# AUX_EVCTL register map
Vendor: Texas Instruments
Peripheral module from a debugger description file (folder CC26x1x3).
Registers are 32-bit, access per field, reset 0x0 unless marked. A register's access mark holds for its fields unless they carry their own. Offsets are as the file gives them; lines under a group give offsets from that group; [hi:lo] are bit positions; {n}, {i} and the like mark numbered series; 'fields as' and 'values as' point back to an identical list; <NAME> marks a mode.

## AUX_EVCTL — AUX Event Controller (AUX_EVCTL) assembles events originating from: - AUX submodules, including ADC and comparators. - AUXIO. - EVENT. - AON_PMCTL. - AON_RTC. into two 64-bit event buses. One is synchronized to the AUX clock and one is left unsynchronized. The subscribers to the synchronous event bus are AUX_TIMER01 and AUX_EVCTL. The subscribers to the asynchronous event bus are AUX_ANAIF, AUX_TDC and AUX_SYSIF. AUX_EVCTL uses the synchronous event bus to generate events to AON_EVENT and EVENT.
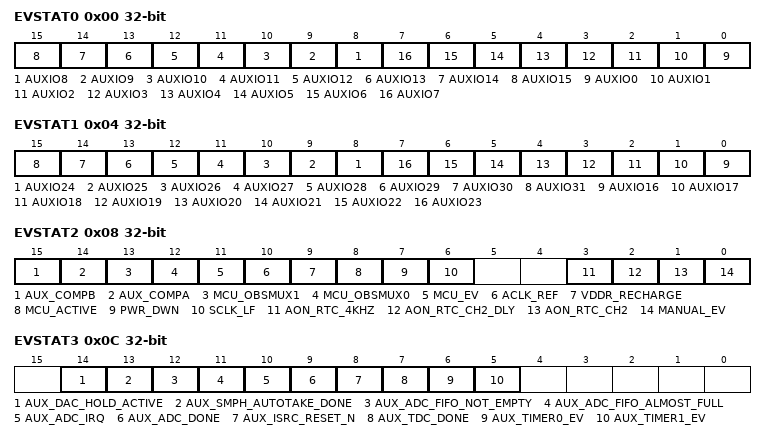
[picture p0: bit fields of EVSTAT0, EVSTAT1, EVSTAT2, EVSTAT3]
0x00 EVSTAT0 ro — Event Status 0 Register holds events 0 thru 15 of the 64-bit event bus that is synchronous to AUX clock. All events read through this register are synchronized at SCE clock rate, unless otherwise noted. The following subscribers use the asynchronous version of events in this register. - AUX_ANAIF. - AUX_TDC. - AUX_SYSIF. - AUX_AIODIOn. - EVOBSCFG.
  [n] AUXIO{n} (n=8..15) — AUXIO{n} pin level, read value corresponds to AUX_AIODIO1:GPIODIN bit {n-8}.
  [n] AUXIO{n} (n=0..7) — AUXIO{n} pin level, read value corresponds to AUX_AIODIO0:GPIODIN bit {n}.
0x04 EVSTAT1 ro — Event Status 1 Register holds events 16 thru 31 of the 64-bit event bus that is synchronous to AUX clock. All events read through this register are synchronized at SCE clock rate, unless otherwise noted. The following subscribers use the asynchronous version of events in this register. - AUX_ANAIF. - AUX_TDC. - AUX_SYSIF. - AUX_AIODIOn. - EVOBSCFG.
  [n-16] AUXIO{n} (n=24..31) — AUXIO{n} pin level, read value corresponds to AUX_AIODIO3:GPIODIN bit {n-24}.
  [n-16] AUXIO{n} (n=16..23) — AUXIO{n} pin level, read value corresponds to AUX_AIODIO2:GPIODIN bit {n-16}.
0x08 EVSTAT2 ro — Event Status 2 Register holds events 32 thru 47 of the 64-bit event bus that is synchronous to AUX clock. All events read through this register are synchronized at SCE clock rate, unless otherwise noted. The following subscribers use the asynchronous version of events in this register. - AUX_ANAIF. - AUX_TDC. - AUX_SYSIF. - AUX_AIODIOn. - EVOBSCFG.
  [15] AUX_COMPB — Comparator B output. Configuration of AUX_SYSIF:EVSYNCRATE.AUX_COMPB_SYNC_RATE sets the synchronization rate for this event.
  [14] AUX_COMPA — Comparator A output. Configuration of AUX_SYSIF:EVSYNCRATE.AUX_COMPA_SYNC_RATE sets the synchronization rate for this event.
  [13] MCU_OBSMUX1 — Observation input 1 from IOC. This event is configured by IOC:OBSAUXOUTPUT.SEL1.
  [12] MCU_OBSMUX0 — Observation input 0 from IOC. This event is configured by IOC:OBSAUXOUTPUT.SEL0 and can be overridden by IOC:OBSAUXOUTPUT.SEL_MISC.
  [11] MCU_EV — Event from EVENT configured by EVENT:AUXSEL0.
  [10] ACLK_REF — TDC reference clock. It is configured by DDI_0_OSC:CTL0.ACLK_REF_SRC_SEL and enabled by AUX_SYSIF:TDCREFCLKCTL.REQ.
  [9] VDDR_RECHARGE — Event is high during VDDR recharge.
  [8] MCU_ACTIVE — Event is high while system(MCU, AUX, or JTAG domains) is active or transitions to active (GLDO or DCDC power supply state). Event is not high during VDDR recharge.
  [7] PWR_DWN — Event is high while system(MCU, AUX, or JTAG domains) is in powerdown (uLDO power supply).
  [6] SCLK_LF — SCLK_LF clock
  [3] AON_RTC_4KHZ — AON_RTC:SUBSEC.VALUE bit 19. AON_RTC:CTL.RTC_4KHZ_EN enables this event.
  [2] AON_RTC_CH2_DLY — AON_RTC:EVFLAGS.CH2 delayed by AON_RTC:CTL.EV_DELAY configuration.
  [1] AON_RTC_CH2 — AON_RTC:EVFLAGS.CH2.
  [0] MANUAL_EV — Programmable event. See MANUAL for description.
0x0C EVSTAT3 ro — Event Status 3 Register holds events 48 thru 63 of the 64-bit event bus that is synchronous to AUX clock. All events read through this register are synchronized at SCE clock rate, unless otherwise noted. The following subscribers use the asynchronous version of events in this register. - AUX_ANAIF. - AUX_TDC . - AUX_SYSIF. - AUX_AIODIOn. - EVOBSCFG.
  [14] AUX_DAC_HOLD_ACTIVE — AUX_ANAIF:DACSTAT.HOLD_ACTIVE
  [13] AUX_SMPH_AUTOTAKE_DONE — See AUX_SMPH:AUTOTAKE.SMPH_ID for description.
  [12] AUX_ADC_FIFO_NOT_EMPTY — AUX_ANAIF:ADCFIFOSTAT.EMPTY negated
  [11] AUX_ADC_FIFO_ALMOST_FULL — AUX_ANAIF:ADCFIFOSTAT.ALMOST_FULL
  [10] AUX_ADC_IRQ — The logical function for this event is configurable. When DMACTL.EN = 1 : Event = UDMA0 Channel 7 done event OR AUX_ANAIF:ADCFIFOSTAT.OVERFLOW OR AUX_ANAIF:ADCFIFOSTAT.UNDERFLOW When DMACTL.EN = 0 : Event = (NOT AUX_ANAIF:ADCFIFOSTAT.EMPTY) OR AUX_ANAIF:ADCFIFOSTAT.OVERFLOW OR AUX_ANAIF:ADCFIFOSTAT.UNDERFLOW Bit 7 in UDMA0:DONEMASK must be 0.
  [9] AUX_ADC_DONE — AUX_ANAIF ADC conversion done event. Event is synchronized at AUX bus rate.
  [8] AUX_ISRC_RESET_N — AUX_ANAIF:ISRCCTL.RESET_N
  [7] AUX_TDC_DONE — AUX_TDC:STAT.DONE
  [6] AUX_TIMER0_EV — AUX_TIMER0_EV event, see AUX_TIMER01:T0TARGET for description.
  [5] AUX_TIMER1_EV — AUX_TIMER1_EV event, see AUX_TIMER01:T1TARGET for description.
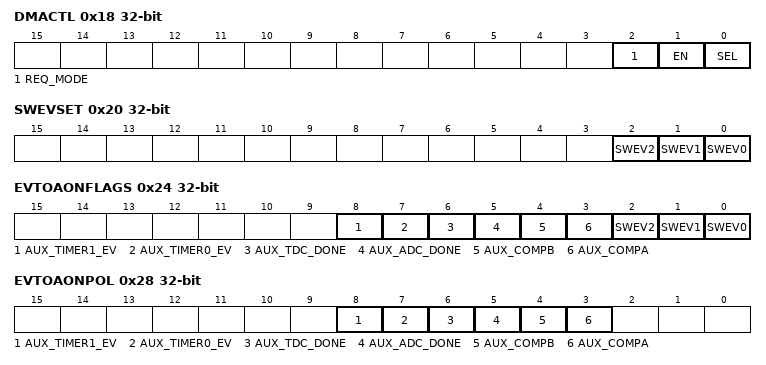
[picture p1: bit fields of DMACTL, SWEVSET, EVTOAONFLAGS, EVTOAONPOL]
0x18 DMACTL — Direct Memory Access Control
  [2] REQ_MODE rw — UDMA0 Request mode
    1=SINGLE (Single requests are generated on UDMA0 channel 7 when the condition configured in SEL is met.); 0=BURST (Burst requests are generated on UDMA0 channel 7 when the condition configured in SEL is met.)
  [1] EN rw — uDMA ADC interface enable. 0: Disable UDMA0 interface to ADC. 1: Enable UDMA0 interface to ADC.
  [0] SEL rw — Select FIFO watermark level required to trigger a UDMA0 transfer of ADC FIFO data.
    1=AUX_ADC_FIFO_ALMOST_FULL (UDMA0 trigger event will be generated when the ADC FIFO is almost full (3/4 full).); 0=AUX_ADC_FIFO_NOT_EMPTY (UDMA0 trigger event will be generated when there are samples in the ADC FIFO.)
0x20 SWEVSET — Software Event Set Set software event flags from AUX domain to AON and MCU domains. CPUs in MCU domain can read the event flags from EVTOAONFLAGS and clear them in EVTOAONFLAGSCLR. Use of these event flags is software-defined.
  [2] SWEV2 wo — Software event flag 2. 0: No effect. 1: Set software event flag 2.
  [1] SWEV1 wo — Software event flag 1. 0: No effect. 1: Set software event flag 1.
  [0] SWEV0 wo — Software event flag 0. 0: No effect. 1: Set software event flag 0.
0x24 EVTOAONFLAGS — Events To AON Flags This register contains a collection of event flags routed to AON_EVENT. To clear an event flag, write to EVTOAONFLAGSCLR or write 0 to event flag in this register.
  [8] AUX_TIMER1_EV rw — This event flag is set when level selected by EVTOAONPOL.AUX_TIMER1_EV occurs on EVSTAT3.AUX_TIMER1_EV.
  [7] AUX_TIMER0_EV rw — This event flag is set when level selected by EVTOAONPOL.AUX_TIMER0_EV occurs on EVSTAT3.AUX_TIMER0_EV.
  [6] AUX_TDC_DONE rw — This event flag is set when level selected by EVTOAONPOL.AUX_TDC_DONE occurs on EVSTAT3.AUX_TDC_DONE.
  [5] AUX_ADC_DONE rw — This event flag is set when level selected by EVTOAONPOL.AUX_ADC_DONE occurs on EVSTAT3.AUX_ADC_DONE.
  [4] AUX_COMPB rw — This event flag is set when edge selected by EVTOAONPOL.AUX_COMPB occurs on EVSTAT2.AUX_COMPB.
  [3] AUX_COMPA rw — This event flag is set when edge selected by EVTOAONPOL.AUX_COMPA occurs on EVSTAT2.AUX_COMPA.
  [2] SWEV2 rw — This event flag is set when software writes a 1 to SWEVSET.SWEV2.
  [1] SWEV1 rw — This event flag is set when software writes a 1 to SWEVSET.SWEV1.
  [0] SWEV0 rw — This event flag is set when software writes a 1 to SWEVSET.SWEV0.
0x28 EVTOAONPOL — Events To AON Polarity Event source polarity configuration for EVTOAONFLAGS.
  [8] AUX_TIMER1_EV rw — Select the level of EVSTAT3.AUX_TIMER1_EV that sets EVTOAONFLAGS.AUX_TIMER1_EV.
    1=LOW (Low level); 0=HIGH (High level)
  [7] AUX_TIMER0_EV rw — Select the level of EVSTAT3.AUX_TIMER0_EV that sets EVTOAONFLAGS.AUX_TIMER0_EV.
    1=LOW (Low level); 0=HIGH (High level)
  [6] AUX_TDC_DONE rw — Select level of EVSTAT3.AUX_TDC_DONE that sets EVTOAONFLAGS.AUX_TDC_DONE.
    1=LOW (Low level); 0=HIGH (High level)
  [5] AUX_ADC_DONE rw — Select the level of EVSTAT3.AUX_ADC_DONE that sets EVTOAONFLAGS.AUX_ADC_DONE.
    1=LOW (Low level); 0=HIGH (High level)
  [4] AUX_COMPB rw — Select the edge of EVSTAT2.AUX_COMPB that sets EVTOAONFLAGS.AUX_COMPB.
    1=FALL (Falling edge); 0=RISE (Rising edge)
  [3] AUX_COMPA rw — Select the edge of EVSTAT2.AUX_COMPA that sets EVTOAONFLAGS.AUX_COMPA.
    1=FALL (Falling edge); 0=RISE (Rising edge)
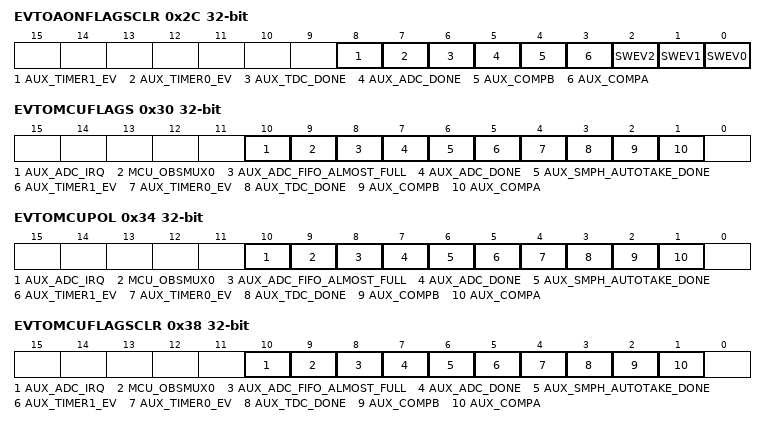
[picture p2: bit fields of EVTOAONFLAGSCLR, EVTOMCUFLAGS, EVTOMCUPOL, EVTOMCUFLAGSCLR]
0x2C EVTOAONFLAGSCLR — Events To AON Clear Clear event flags in EVTOAONFLAGS. In order to clear a level sensitive event flag, the event must be deasserted.
  [8] AUX_TIMER1_EV wo — Write 1 to clear EVTOAONFLAGS.AUX_TIMER1_EV. Read value is 0.
  [7] AUX_TIMER0_EV wo — Write 1 to clear EVTOAONFLAGS.AUX_TIMER0_EV. Read value is 0.
  [6] AUX_TDC_DONE wo — Write 1 to clear EVTOAONFLAGS.AUX_TDC_DONE. Read value is 0.
  [5] AUX_ADC_DONE wo — Write 1 to clear EVTOAONFLAGS.AUX_ADC_DONE. Read value is 0.
  [4] AUX_COMPB wo — Write 1 to clear EVTOAONFLAGS.AUX_COMPB. Read value is 0.
  [3] AUX_COMPA wo — Write 1 to clear EVTOAONFLAGS.AUX_COMPA. Read value is 0.
  [2] SWEV2 wo — Write 1 to clear EVTOAONFLAGS.SWEV2. Read value is 0.
  [1] SWEV1 wo — Write 1 to clear EVTOAONFLAGS.SWEV1. Read value is 0.
  [0] SWEV0 wo — Write 1 to clear EVTOAONFLAGS.SWEV0. Read value is 0.
0x30 EVTOMCUFLAGS — Events to MCU Flags This register contains a collection of event flags routed to MCU domain. To clear an event flag, write to EVTOMCUFLAGSCLR or write 0 to event flag in this register. Follow procedure described in AUX_SYSIF:WUCLR to clear AUX_WU_EV event flag.
  [10] AUX_ADC_IRQ rw — This event flag is set when level selected by EVTOMCUPOL.AUX_ADC_IRQ occurs on EVSTAT3.AUX_ADC_IRQ.
  [9] MCU_OBSMUX0 rw — This event flag is set when level selected by EVTOMCUPOL.MCU_OBSMUX0 occurs on EVSTAT2.MCU_OBSMUX0.
  [8] AUX_ADC_FIFO_ALMOST_FULL rw — This event flag is set when level selected by EVTOMCUPOL.AUX_ADC_FIFO_ALMOST_FULL occurs on EVSTAT3.AUX_ADC_FIFO_ALMOST_FULL.
  [7] AUX_ADC_DONE rw — This event flag is set when level selected by EVTOMCUPOL.AUX_ADC_DONE occurs on EVSTAT3.AUX_ADC_DONE.
  [6] AUX_SMPH_AUTOTAKE_DONE rw — This event flag is set when level selected by EVTOMCUPOL.AUX_SMPH_AUTOTAKE_DONE occurs on EVSTAT3.AUX_SMPH_AUTOTAKE_DONE.
  [5] AUX_TIMER1_EV rw — This event flag is set when level selected by EVTOMCUPOL.AUX_TIMER1_EV occurs on EVSTAT3.AUX_TIMER1_EV.
  [4] AUX_TIMER0_EV rw — This event flag is set when level selected by EVTOMCUPOL.AUX_TIMER0_EV occurs on EVSTAT3.AUX_TIMER0_EV.
  [3] AUX_TDC_DONE rw — This event flag is set when level selected by EVTOMCUPOL.AUX_TDC_DONE occurs on EVSTAT3.AUX_TDC_DONE.
  [2] AUX_COMPB rw — This event flag is set when edge selected by EVTOMCUPOL.AUX_COMPB occurs on EVSTAT2.AUX_COMPB.
  [1] AUX_COMPA rw — This event flag is set when edge selected by EVTOMCUPOL.AUX_COMPA occurs on EVSTAT2.AUX_COMPA.
0x34 EVTOMCUPOL — Event To MCU Polarity Event source polarity configuration for EVTOMCUFLAGS.
  [10] AUX_ADC_IRQ rw — Select the event source level that sets EVTOMCUFLAGS.AUX_ADC_IRQ.
    1=LOW (Low level); 0=HIGH (High level)
  [9] MCU_OBSMUX0 rw — Select the event source level that sets EVTOMCUFLAGS.MCU_OBSMUX0.
    1=LOW (Low level); 0=HIGH (High level)
  [8] AUX_ADC_FIFO_ALMOST_FULL rw — Select the event source level that sets EVTOMCUFLAGS.AUX_ADC_FIFO_ALMOST_FULL.
    1=LOW (Low level); 0=HIGH (High level)
  [7] AUX_ADC_DONE rw — Select the event source level that sets EVTOMCUFLAGS.AUX_ADC_DONE.
    1=LOW (Low level); 0=HIGH (High level)
  [6] AUX_SMPH_AUTOTAKE_DONE rw — Select the event source level that sets EVTOMCUFLAGS.AUX_SMPH_AUTOTAKE_DONE.
    1=LOW (Low level); 0=HIGH (High level)
  [5] AUX_TIMER1_EV rw — Select the event source level that sets EVTOMCUFLAGS.AUX_TIMER1_EV.
    1=LOW (Low level); 0=HIGH (High level)
  [4] AUX_TIMER0_EV rw — Select the event source level that sets EVTOMCUFLAGS.AUX_TIMER0_EV.
    1=LOW (Low level); 0=HIGH (High level)
  [3] AUX_TDC_DONE rw — Select the event source level that sets EVTOMCUFLAGS.AUX_TDC_DONE.
    1=LOW (Low level); 0=HIGH (High level)
  [2] AUX_COMPB rw — Select the event source edge that sets EVTOMCUFLAGS.AUX_COMPB.
    1=FALL (Falling edge); 0=RISE (Rising edge)
  [1] AUX_COMPA rw — Select the event source edge that sets EVTOMCUFLAGS.AUX_COMPA.
    1=FALL (Falling edge); 0=RISE (Rising edge)
0x38 EVTOMCUFLAGSCLR — Events To MCU Flags Clear Clear event flags in EVTOMCUFLAGS. In order to clear a level sensitive event flag, the event must be deasserted.
  [10] AUX_ADC_IRQ wo — Write 1 to clear EVTOMCUFLAGS.AUX_ADC_IRQ. Read value is 0.
  [9] MCU_OBSMUX0 wo — Write 1 to clear EVTOMCUFLAGS.MCU_OBSMUX0. Read value is 0.
  [8] AUX_ADC_FIFO_ALMOST_FULL wo — Write 1 to clear EVTOMCUFLAGS.AUX_ADC_FIFO_ALMOST_FULL. Read value is 0.
  [7] AUX_ADC_DONE wo — Write 1 to clear EVTOMCUFLAGS.AUX_ADC_DONE. Read value is 0.
  [6] AUX_SMPH_AUTOTAKE_DONE wo — Write 1 to clear EVTOMCUFLAGS.AUX_SMPH_AUTOTAKE_DONE. Read value is 0.
  [5] AUX_TIMER1_EV wo — Write 1 to clear EVTOMCUFLAGS.AUX_TIMER1_EV. Read value is 0.
  [4] AUX_TIMER0_EV wo — Write 1 to clear EVTOMCUFLAGS.AUX_TIMER0_EV. Read value is 0.
  [3] AUX_TDC_DONE wo — Write 1 to clear EVTOMCUFLAGS.AUX_TDC_DONE. Read value is 0.
  [2] AUX_COMPB wo — Write 1 to clear EVTOMCUFLAGS.AUX_COMPB. Read value is 0.
  [1] AUX_COMPA wo — Write 1 to clear EVTOMCUFLAGS.AUX_COMPA. Read value is 0.
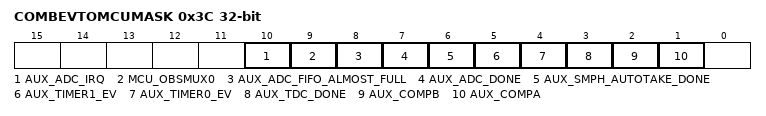
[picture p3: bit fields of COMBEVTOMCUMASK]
0x3C COMBEVTOMCUMASK — Combined Event To MCU Mask Select event flags in EVTOMCUFLAGS that contribute to the AUX_COMB event to EVENT and system CPU. The AUX_COMB event is high as long as one or more of the included event flags are set.
  [10] AUX_ADC_IRQ rw — EVTOMCUFLAGS.AUX_ADC_IRQ contribution to the AUX_COMB event. 0: Exclude. 1: Include.
  [9] MCU_OBSMUX0 rw — EVTOMCUFLAGS.MCU_OBSMUX0 contribution to the AUX_COMB event. 0: Exclude. 1: Include.
  [8] AUX_ADC_FIFO_ALMOST_FULL rw — EVTOMCUFLAGS.AUX_ADC_FIFO_ALMOST_FULL contribution to the AUX_COMB event. 0: Exclude. 1: Include.
  [7] AUX_ADC_DONE rw — EVTOMCUFLAGS.AUX_ADC_DONE contribution to the AUX_COMB event. 0: Exclude. 1: Include.
  [6] AUX_SMPH_AUTOTAKE_DONE rw — EVTOMCUFLAGS.AUX_SMPH_AUTOTAKE_DONE contribution to the AUX_COMB event. 0: Exclude. 1: Include.
  [5] AUX_TIMER1_EV rw — EVTOMCUFLAGS.AUX_TIMER1_EV contribution to the AUX_COMB event. 0: Exclude. 1: Include.
  [4] AUX_TIMER0_EV rw — EVTOMCUFLAGS.AUX_TIMER0_EV contribution to the AUX_COMB event. 0: Exclude. 1: Include.
  [3] AUX_TDC_DONE rw — EVTOMCUFLAGS.AUX_TDC_DONE contribution to the AUX_COMB event. 0: Exclude. 1: Include.
  [2] AUX_COMPB rw — EVTOMCUFLAGS.AUX_COMPB contribution to the AUX_COMB event. 0: Exclude 1: Include.
  [1] AUX_COMPA rw — EVTOMCUFLAGS.AUX_COMPA contribution to the AUX_COMB event. 0: Exclude. 1: Include.
0x40 EVOBSCFG — Event Observation Configuration
  [5:0] EVOBS_SEL rw — Select which event from the asynchronous event bus that represents AUX_EV_OBS in AUX_AIODIOn.
    62=AUX_DAC_HOLD_ACTIVE (EVSTAT3.AUX_DAC_HOLD_ACTIVE); 61=AUX_SMPH_AUTOTAKE_DONE (EVSTAT3.AUX_SMPH_AUTOTAKE_DONE); 60=AUX_ADC_FIFO_NOT_EMPTY (EVSTAT3.AUX_ADC_FIFO_NOT_EMPTY); 59=AUX_ADC_FIFO_ALMOST_FULL (EVSTAT3.AUX_ADC_FIFO_ALMOST_FULL); 58=AUX_ADC_IRQ (EVSTAT3.AUX_ADC_IRQ); 57=AUX_ADC_DONE (EVSTAT3.AUX_ADC_DONE); 56=AUX_ISRC_RESET_N (EVSTAT3.AUX_ISRC_RESET_N); 55=AUX_TDC_DONE (EVSTAT3.AUX_TDC_DONE); 54=AUX_TIMER0_EV (EVSTAT3.AUX_TIMER0_EV); 53=AUX_TIMER1_EV (EVSTAT3.AUX_TIMER1_EV); 47=AUX_COMPB (EVSTAT2.AUX_COMPB); 46=AUX_COMPA (EVSTAT2.AUX_COMPA); 45=MCU_OBSMUX1 (EVSTAT2.MCU_OBSMUX1); 44=MCU_OBSMUX0 (EVSTAT2.MCU_OBSMUX0); 43=MCU_EV (EVSTAT2.MCU_EV); 42=ACLK_REF (EVSTAT2.ACLK_REF); 41=VDDR_RECHARGE (EVSTAT2.VDDR_RECHARGE); 40=MCU_ACTIVE (EVSTAT2.MCU_ACTIVE); 39=PWR_DWN (EVSTAT2.PWR_DWN); 38=SCLK_LF (EVSTAT2.SCLK_LF); 35=AON_RTC_4KHZ (EVSTAT2.AON_RTC_4KHZ); 34=AON_RTC_CH2_DLY (EVSTAT2.AON_RTC_CH2_DLY); 33=AON_RTC_CH2 (EVSTAT2.AON_RTC_CH2); 32=MANUAL_EV (EVSTAT2.MANUAL_EV); {v}=AUXIO{v} (EVSTAT1.AUXIO{v}) (v=16..31); {v}=AUXIO{v} (EVSTAT0.AUXIO{v}) (v=0..15)
0x48 MANUAL — Manual Programmable event.
  [0] EV rw — This bit field sets the value of EVSTAT2.MANUAL_EV.
